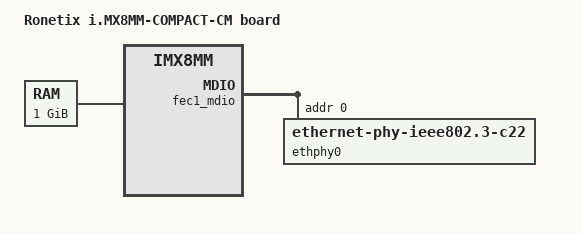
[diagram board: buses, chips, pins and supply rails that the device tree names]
// SPDX-License-Identifier: (GPL-2.0+ OR MIT)
/*
 * Copyright 2019 NXP
 * Copyright 2026 Ronetix GmbH
 */

/dts-v1/;

#include "imx8mm-compact-cm.dtsi"

/ {
	model = "Ronetix i.MX8MM-COMPACT-CM board";
	compatible = "ronetix,imx8mm-compact-cm", "fsl,imx8mm";

	memory@40000000 {
		device_type = "memory";
		reg = <0x0 0x40000000 0 0x40000000>;
	};
};

&fec1_mdio {
	/* AR8031 */
	ethphy0: ethernet-phy@0 {
		compatible = "ethernet-phy-ieee802.3-c22";
		reg = <0>;
	};
};
